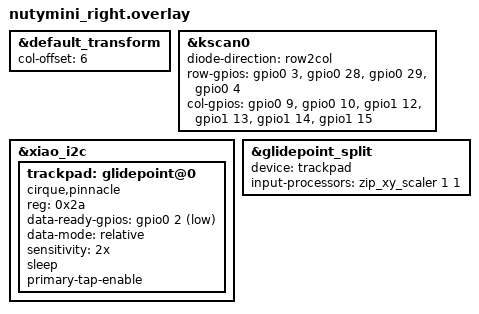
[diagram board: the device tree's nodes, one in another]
/*
 * Copyright (c) 2020 Pete Johanson
 *
 * SPDX-License-Identifier: MIT
 */


#include <input/processors.dtsi>
#include <dt-bindings/zmk/input_transform.h>

#include "nutymini.dtsi"
#include "nutymini-pinctrl_right.dtsi"
#include <input/processors.dtsi>
#include <zephyr/dt-bindings/input/input-event-codes.h>

&default_transform {
	col-offset = <6>;
};


&kscan0 {

  diode-direction = "row2col";
  row-gpios
    = <&gpio0 3 GPIO_ACTIVE_HIGH >     //Row0
    , <&gpio0 28 GPIO_ACTIVE_HIGH >     //Row1
    , <&gpio0 29 GPIO_ACTIVE_HIGH >    //Row2
    , <&gpio0 4 GPIO_ACTIVE_HIGH >    //Row3
    ;
	col-gpios
		= <&gpio0 9  (GPIO_ACTIVE_HIGH |GPIO_PULL_DOWN)>	//Col0
		, <&gpio0 10 (GPIO_ACTIVE_HIGH |GPIO_PULL_DOWN)>  //Col1
		, <&gpio1 12 (GPIO_ACTIVE_HIGH |GPIO_PULL_DOWN)>  //Col2
		, <&gpio1 13 (GPIO_ACTIVE_HIGH |GPIO_PULL_DOWN)>  //Col3
		, <&gpio1 14 (GPIO_ACTIVE_HIGH |GPIO_PULL_DOWN)>  //Col4
		, <&gpio1 15 (GPIO_ACTIVE_HIGH |GPIO_PULL_DOWN)>  //Col5
		;
};


&xiao_i2c {
    status = "okay";

    trackpad: glidepoint@0 { 
        compatible = "cirque,pinnacle";
        status = "okay";
        reg = <0x2a>;
        data-ready-gpios= <&gpio0 2 (GPIO_ACTIVE_LOW)>;
        //dr-gpios= <&gpio0 2 (GPIO_ACTIVE_LOW)>;
        data-mode = "relative";
        sensitivity = "2x";
        sleep;
        //no-taps;
        primary-tap-enable;
    };
};

&glidepoint_split {
    device = <&trackpad>;
    input-processors = <&zip_xy_scaler 1 1>;
    //status = "disabled";
};


